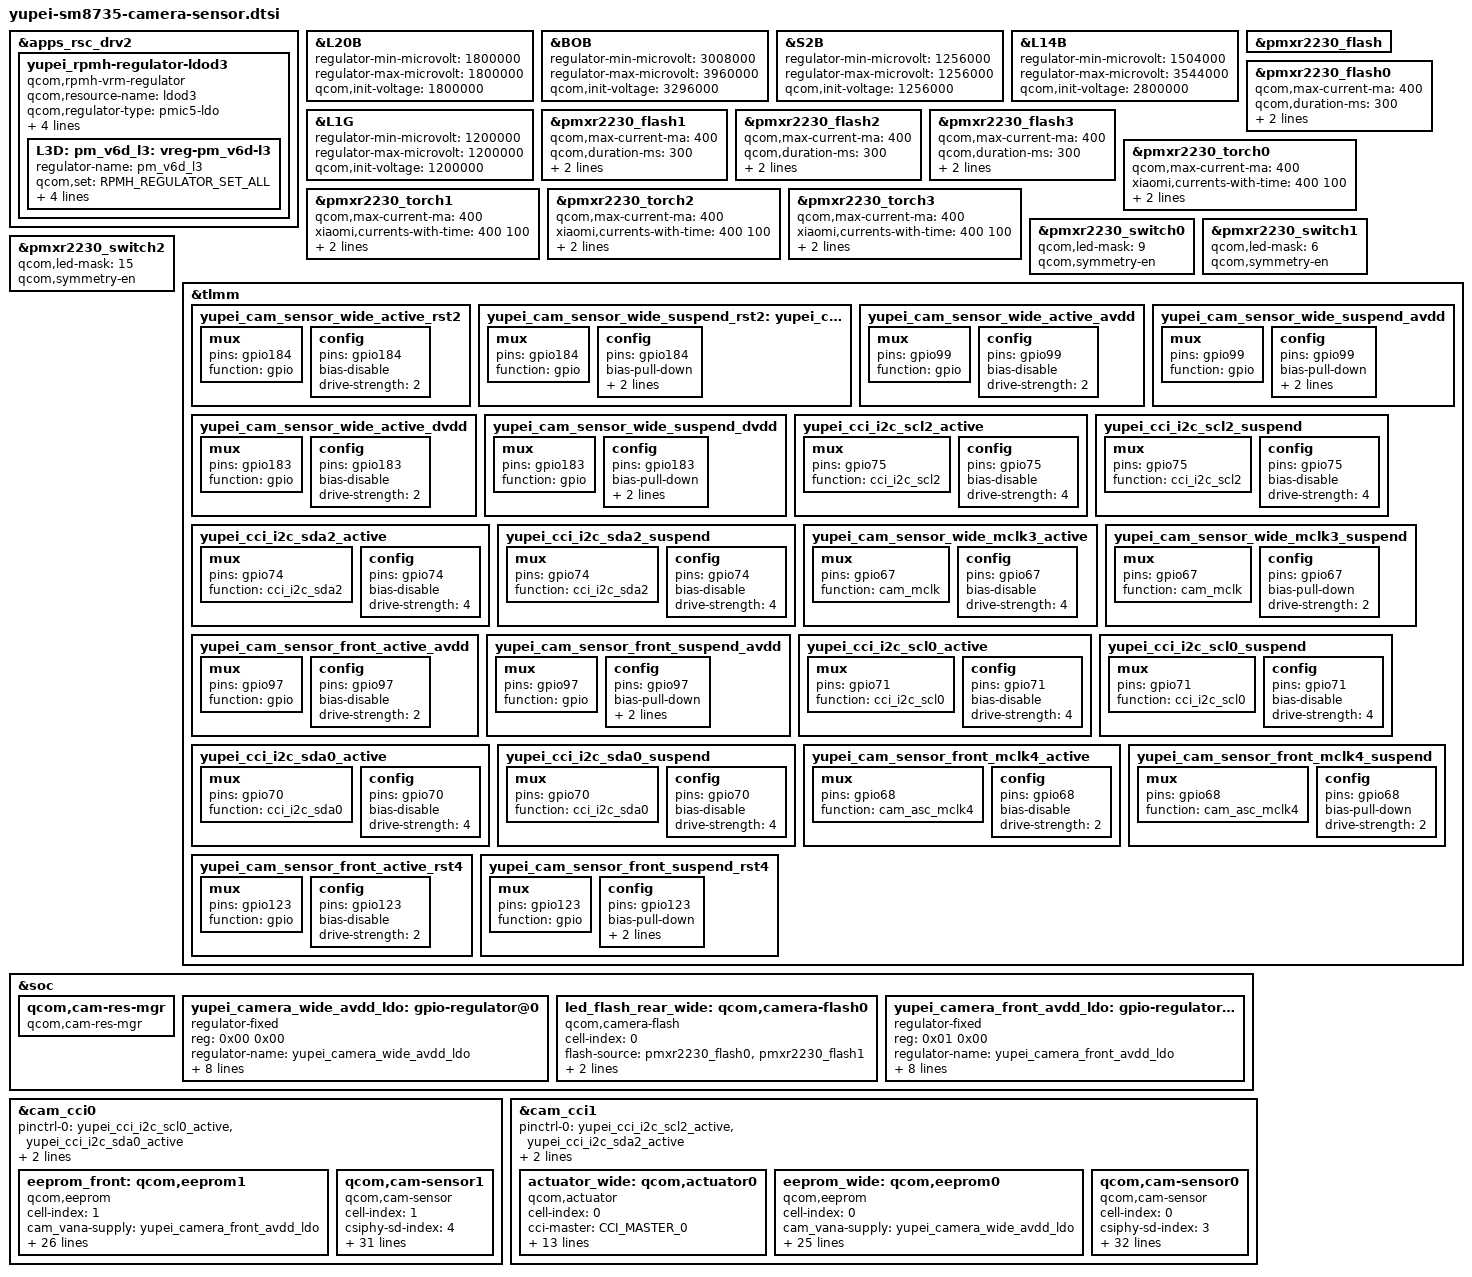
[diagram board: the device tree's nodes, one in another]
#include <dt-bindings/msm-camera.h>

&apps_rsc_drv2 {
	yupei_rpmh-regulator-ldod3 {
		compatible = "qcom,rpmh-vrm-regulator";
		qcom,resource-name = "ldod3";
		qcom,regulator-type = "pmic5-ldo";
		qcom,supported-modes =
			<RPMH_REGULATOR_MODE_LPM
			 RPMH_REGULATOR_MODE_HPM>;
		qcom,mode-threshold-currents = <0 30000>;
		proxy-supply = <&L3D>;

		L3D: pm_v6d_l3: vreg-pm_v6d-l3 {
			regulator-name = "pm_v6d_l3";
			qcom,set = <RPMH_REGULATOR_SET_ALL>;
			regulator-min-microvolt = <1030000>;
			regulator-max-microvolt = <1100000>;
			qcom,init-voltage = <1060000>;
			qcom,init-mode = <RPMH_REGULATOR_MODE_HPM>;
		};
	};
};

&L20B{
	regulator-min-microvolt = <1800000>;
	regulator-max-microvolt = <1800000>;
	qcom,init-voltage = <1800000>;
};

&BOB{
	regulator-min-microvolt = <3008000>;
	regulator-max-microvolt = <3960000>;
	qcom,init-voltage = <3296000>;
};
&S2B{
	regulator-min-microvolt = <1256000>;
	regulator-max-microvolt = <1256000>;
	qcom,init-voltage = <1256000>;
};

&L3D{
	regulator-min-microvolt = <1200000>;
	regulator-max-microvolt = <1200000>;
	qcom,init-voltage = <1200000>;
};

&L14B{
	regulator-min-microvolt = <1504000>;
	regulator-max-microvolt = <3544000>;
	qcom,init-voltage = <2800000>;
	status = "ok";
};

&L1G{
	regulator-min-microvolt = <1200000>;
	regulator-max-microvolt = <1200000>;
	qcom,init-voltage = <1200000>;
};

&pmxr2230_flash {
	status = "ok";
};

&pmxr2230_flash0 {
	qcom,max-current-ma = <400>;
	qcom,duration-ms = <300>;
	xiaomi,max-duration-ms = <300>;
	qcom,ires-ua = <5000>;
};
&pmxr2230_flash1 {
        qcom,max-current-ma = <400>;
        qcom,duration-ms = <300>;
        xiaomi,max-duration-ms = <300>;
        qcom,ires-ua = <5000>;
};
&pmxr2230_flash2 {
        qcom,max-current-ma = <400>;
        qcom,duration-ms = <300>;
        xiaomi,max-duration-ms = <300>;
        qcom,ires-ua = <5000>;
};
&pmxr2230_flash3 {
        qcom,max-current-ma = <400>;
        qcom,duration-ms = <300>;
        xiaomi,max-duration-ms = <300>;
        qcom,ires-ua = <5000>;
};

&pmxr2230_torch0{
	qcom,max-current-ma = <400>;
	xiaomi,currents-with-time = <400 100>;
	xiaomi,time-for-currents = <5000 0xFFFFFFFF>;  /* 0xFFFFFFFF means flash always on*/
	qcom,ires-ua = <5000>;
};
&pmxr2230_torch1{
	qcom,max-current-ma = <400>;
	xiaomi,currents-with-time = <400 100>;
	xiaomi,time-for-currents = <5000 0xFFFFFFFF>;  /* 0xFFFFFFFF means flash always on*/
	qcom,ires-ua = <5000>;
};
&pmxr2230_torch2{
	qcom,max-current-ma = <400>;
	xiaomi,currents-with-time = <400 100>;
	xiaomi,time-for-currents = <5000 0xFFFFFFFF>;  /* 0xFFFFFFFF means flash always on*/
	qcom,ires-ua = <5000>;
};
&pmxr2230_torch3{
        qcom,max-current-ma = <400>;
        xiaomi,currents-with-time = <400 100>;
        xiaomi,time-for-currents = <5000 0xFFFFFFFF>;  /* 0xFFFFFFFF means flash always on*/
        qcom,ires-ua = <5000>;
};

&pmxr2230_switch0 {
	qcom,led-mask = <9>; // Channels 1 & 4
	qcom,symmetry-en;
};
&pmxr2230_switch1 {
	qcom,led-mask = <6>; // Channels 2 & 3
	qcom,symmetry-en;
};
&pmxr2230_switch2 {
	qcom,led-mask = <15>; // Channels All
	qcom,symmetry-en;
};


&tlmm {
		yupei_cam_sensor_wide_active_rst2: yupei_cam_sensor_wide_active_rst2 {
		mux {
			pins = "gpio184";
			function = "gpio";
		};
		config {
			pins = "gpio184";
			bias-disable; /* No PULL */
			drive-strength = <2>; /* 2 MA */
		};
	};
	yupei_cam_sensor_wide_suspend_rst2: yupei_cam_sensor_front_suspend_rst2 {
		mux {
			pins = "gpio184";
			function = "gpio";
		};
		config {
			pins = "gpio184";
			bias-pull-down; /* PULL DOWN */
			drive-strength = <2>; /* 2 MA */
			output-low;
		};
	};

	yupei_cam_sensor_wide_active_avdd: yupei_cam_sensor_wide_active_avdd {
		mux {
			pins = "gpio99";
			function = "gpio";
		};

		config {
			pins = "gpio99";
			bias-disable; /* No PULL */
			drive-strength = <2>; /* 2 MA */
		};
	};

	yupei_cam_sensor_wide_suspend_avdd: yupei_cam_sensor_wide_suspend_avdd {
		mux {
			pins = "gpio99";
			function = "gpio";
		};

		config {
			pins = "gpio99";
			bias-pull-down; /* PULL DOWN */
			drive-strength = <2>; /* 2 MA */
			output-low;
		};
	};


	yupei_cam_sensor_wide_active_dvdd: yupei_cam_sensor_wide_active_dvdd {
		mux {
			pins = "gpio183";
			function = "gpio";
		};

		config {
			pins = "gpio183";
			bias-disable; /* No PULL */
			drive-strength = <2>; /* 2 MA */
		};
	};

	yupei_cam_sensor_wide_suspend_dvdd: yupei_cam_sensor_wide_suspend_dvdd {
		mux {
			pins = "gpio183";
			function = "gpio";
		};

		config {
			pins = "gpio183";
			bias-pull-down; /* PULL DOWN */
			drive-strength = <2>; /* 2 MA */
			output-low;
		};
	};
        
 	yupei_cci_i2c_scl2_active: yupei_cci_i2c_scl2_active {
		mux {
			pins = "gpio75";
			function = "cci_i2c_scl2";
		};
		config {
			pins = "gpio75";
			bias-disable; /* NO PULL */
			drive-strength = <4>; /* 4 MA */
		};
 	};

 	yupei_cci_i2c_scl2_suspend: yupei_cci_i2c_scl2_suspend {
		mux {
			pins = "gpio75";
			function = "cci_i2c_scl2";
		};
		config {
			pins = "gpio75";
			bias-disable; /* NO PULL */
			drive-strength = <4>; /* 4 MA */
		};
 	};     
     
 	yupei_cci_i2c_sda2_active: yupei_cci_i2c_sda2_active {
		mux {
			pins = "gpio74";
			function = "cci_i2c_sda2";
		};
		config {
			pins = "gpio74";
			bias-disable; /* NO PULL */
			drive-strength = <4>; /* 4 MA */
		};
 	};

 	yupei_cci_i2c_sda2_suspend: yupei_cci_i2c_sda2_suspend {
 		mux {
			pins = "gpio74";
			function = "cci_i2c_sda2";
		};
		config {
			pins = "gpio74";
			bias-disable; /* NO PULL */
			drive-strength = <4>; /* 4 MA */
		};
 	};

 	yupei_cam_sensor_wide_mclk3_active: yupei_cam_sensor_wide_mclk3_active {
 		/* MCLK0 */
 		mux {
 			pins = "gpio67";
 			function = "cam_mclk";
 		};

 		config {
 			pins = "gpio67";
 			bias-disable; /* No PULL */
 			drive-strength = <4>; /* 4 MA */
 		};
 	};

 	yupei_cam_sensor_wide_mclk3_suspend: yupei_cam_sensor_wide_mclk3_suspend {
 		/* MCLK0 */
 		mux {
 			pins = "gpio67";
 			function = "cam_mclk";
 		};

 		config {
 			pins = "gpio67";
 			bias-pull-down; /* PULL DOWN */
 			drive-strength = <2>; /* 2 MA */
 		};
 	};

	yupei_cam_sensor_front_active_avdd: yupei_cam_sensor_front_active_avdd {
		mux {
			pins = "gpio97";
			function = "gpio";
		};
		config {
			pins = "gpio97";
			bias-disable; /* No PULL */
			drive-strength = <2>; /* 2 MA */
		};
	};

	yupei_cam_sensor_front_suspend_avdd: yupei_cam_sensor_front_suspend_avdd {
		mux {
			pins = "gpio97";
			function = "gpio";
		};
		config {
			pins = "gpio97";
			bias-pull-down; /* PULL DOWN */
			drive-strength = <2>; /* 2 MA */
			output-low;
		};
	};
        
    yupei_cci_i2c_scl0_active: yupei_cci_i2c_scl0_active {
		mux {
			pins = "gpio71";
			function = "cci_i2c_scl0";
		};

		config {
			pins = "gpio71";
			bias-disable; /* NO PULL */
			drive-strength = <4>; /* 4 MA */
		};
	};

	yupei_cci_i2c_scl0_suspend: yupei_cci_i2c_scl0_suspend {
		mux {
			pins = "gpio71";
			function = "cci_i2c_scl0";
		};
		config {
			pins = "gpio71";
			bias-disable; /* NO PULL */
			drive-strength = <4>; /* 4 MA */
		};
	};

	yupei_cci_i2c_sda0_active: yupei_cci_i2c_sda0_active {
		mux {
			pins = "gpio70";
			function = "cci_i2c_sda0";
		};

		config {
			pins = "gpio70";
			bias-disable; /* NO PULL */
			drive-strength = <4>; /* 4 MA */
		};
	};

	yupei_cci_i2c_sda0_suspend: yupei_cci_i2c_sda0_suspend {
		mux {
			pins = "gpio70";
			function = "cci_i2c_sda0";
		};

		config {
			pins = "gpio70";
			bias-disable; /* NO PULL */
			drive-strength = <4>; /* 4 MA */
		};
	};

	yupei_cam_sensor_front_mclk4_active: yupei_cam_sensor_front_mclk4_active {
		/* MCLK4 */
		mux {
			pins = "gpio68";
			function = "cam_asc_mclk4";
		};
		config {
			pins = "gpio68";
			bias-disable; /* No PULL */
			drive-strength = <2>; /* 2 MA */
		};
	};

	yupei_cam_sensor_front_mclk4_suspend: yupei_cam_sensor_front_mclk4_suspend {
		/* MCLK4 */
		mux {
			pins = "gpio68";
			function = "cam_asc_mclk4";
		};
		config {
			pins = "gpio68";
			bias-pull-down; /* PULL DOWN */
			drive-strength = <2>; /* 2 MA */
		};
	};

	yupei_cam_sensor_front_active_rst4: yupei_cam_sensor_front_active_rst4 {
		mux {
			pins = "gpio123";
			function = "gpio";
		};
		config {
			pins = "gpio123";
			bias-disable; /* No PULL */
			drive-strength = <2>; /* 2 MA */
		};
	};

	yupei_cam_sensor_front_suspend_rst4: yupei_cam_sensor_front_suspend_rst4 {
		mux {
			pins = "gpio123";
			function = "gpio";
		};
		config {
			pins = "gpio123";
			bias-pull-down; /* PULL DOWN */
			drive-strength = <2>; /* 2 MA */
			output-low;
		};
	};

};


&soc {
		qcom,cam-res-mgr {
		compatible = "qcom,cam-res-mgr";
		status = "ok";
	};

	yupei_camera_wide_avdd_ldo: gpio-regulator@0 {
		compatible = "regulator-fixed";
		reg = <0x00 0x00>;
		regulator-name = "yupei_camera_wide_avdd_ldo";
		regulator-min-microvolt = <2800000>;
		regulator-max-microvolt = <2800000>;
		regulator-enable-ramp-delay = <100>;
		enable-active-high;
		gpio = <&tlmm 99 0>;
		pinctrl-names = "yupei_wide_avdd_active", "yupei_wide_avdd_suspend";
		pinctrl-0 = <&yupei_cam_sensor_wide_active_avdd
					 &yupei_cam_sensor_wide_suspend_avdd>;
		vin-supply = <&BOB>;
	};

	/*yupei_camera_wide_dvdd_ldo: gpio-regulator@0 {
		compatible = "regulator-fixed";
		reg = <0x00 0x00>;
		regulator-name = "yupei_camera_wide_dvdd_ldo";
		regulator-min-microvolt = <1200000>;
		regulator-max-microvolt = <1200000>;
		regulator-enable-ramp-delay = <100>;
		enable-active-high;
		gpio = <&tlmm 183 0>;
		pinctrl-names = "yupei_wide_dvdd_active", "yupei_wide_dvdd_suspend";
		pinctrl-0 = <&yupei_cam_sensor_wide_active_dvdd
					 &yupei_cam_sensor_wide_suspend_dvdd>;
		vin-supply = <&BOB &S2B>;

	};*/

	led_flash_rear_wide: qcom,camera-flash0 {
		cell-index = <0>;
		compatible = "qcom,camera-flash";
		flash-source = <&pmxr2230_flash0 &pmxr2230_flash1>;
		torch-source = <&pmxr2230_torch0 &pmxr2230_torch1>;
		switch-source = <&pmxr2230_switch2>;
		status = "ok";
	};

	yupei_camera_front_avdd_ldo: gpio-regulator@1 {
		compatible = "regulator-fixed";
		reg = <0x01 0x00>;
		regulator-name = "yupei_camera_front_avdd_ldo";
		regulator-min-microvolt = <2800000>;
		regulator-max-microvolt = <2800000>;
		regulator-enable-ramp-delay = <100>;
		enable-active-high;
		gpio = <&tlmm 97 0>;
		pinctrl-names = "yupei_front_avdd_active", "yupei_front_avdd_suspend";
		pinctrl-0 = <&yupei_cam_sensor_front_active_avdd
					 &yupei_cam_sensor_front_suspend_avdd>;
		vin-supply = <&BOB>;
	};
};

&cam_cci0 {
	pinctrl-0 = <&yupei_cci_i2c_scl0_active &yupei_cci_i2c_sda0_active>;
	pinctrl-1 = <&yupei_cci_i2c_scl0_suspend &yupei_cci_i2c_sda0_suspend>;

	// front eeprom
	eeprom_front: qcom,eeprom1 {
		cell-index = <1>;
		compatible = "qcom,eeprom";
		cam_vana-supply = <&yupei_camera_front_avdd_ldo>;
		cam_vio-supply = <&L20B>;
		cam_vdig-supply = <&L1G>;
		cam_clk-supply = <&cam_cc_titan_top_gdsc>;
		regulator-names = "cam_vana", "cam_vio", "cam_vdig", "cam_clk";
		rgltr-cntrl-support;
		rgltr-min-voltage = <2800000 1800000 1200000 0>;
		rgltr-max-voltage = <2800000 1800000 1200000 0>;
		rgltr-load-current = <31200 1300 58500 0>;
		gpio-no-mux = <0>;
		pinctrl-names = "cam_default", "cam_suspend";
		pinctrl-0 = <&yupei_cam_sensor_front_mclk4_active
			&yupei_cam_sensor_front_active_rst4>;
		pinctrl-1 = <&yupei_cam_sensor_front_mclk4_suspend
			&yupei_cam_sensor_front_suspend_rst4>;
		gpios = <&tlmm 68 0>, <&tlmm 123 0>;
		gpio-reset = <1>;
		gpio-req-tbl-num = <0 1>;
		gpio-req-tbl-flags = <1 0>;
		gpio-req-tbl-label = "CAMIF_MCLK4", "CAM_RESET4";
		cci-master = <CCI_MASTER_0>;
		clocks = <&cambistmclkcc CAM_BIST_MCLK_CC_MCLK4_CLK>;
		clock-names = "cam_clk";
		clock-cntl-level = "nominal";
		clock-rates = <19200000>;
		status = "ok";
	};

	// front sensor
	qcom,cam-sensor1 {
		cell-index = <1>;
		compatible = "qcom,cam-sensor";
		csiphy-sd-index = <4>;
		eeprom-src = <&eeprom_front>;
		sensor-position-roll = <90>;
		sensor-position-pitch = <0>;
		sensor-position-yaw = <0>;
		cam_vana-supply = <&yupei_camera_front_avdd_ldo>;
		cam_vio-supply = <&L20B>;
		cam_vdig-supply = <&L1G>;
		cam_clk-supply = <&cam_cc_titan_top_gdsc>;
		regulator-names = "cam_vana", "cam_vio", "cam_vdig", "cam_clk";
		rgltr-cntrl-support;
		rgltr-min-voltage = <2800000 1800000 1200000 0>;
		rgltr-max-voltage = <2800000 1800000 1200000 0>;
		rgltr-load-current = <31200 1300 58500 0>;
		gpio-no-mux = <0>;
		pinctrl-names = "cam_default", "cam_suspend";
		pinctrl-0 = <&yupei_cam_sensor_front_mclk4_active
			&yupei_cam_sensor_front_active_rst4>;
		pinctrl-1 = <&yupei_cam_sensor_front_mclk4_suspend
			&yupei_cam_sensor_front_suspend_rst4>;
		gpios = <&tlmm 68 0>, <&tlmm 123 0>;
		gpio-reset = <1>;
		gpio-req-tbl-num = <0 1>;
		gpio-req-tbl-flags = <1 0>;
		gpio-req-tbl-label = "CAMIF_MCLK4", "CAM_RESET4";
		cci-master = <CCI_MASTER_0>;
		clocks = <&cambistmclkcc CAM_BIST_MCLK_CC_MCLK4_CLK>;
		clock-names = "cam_clk";
		clock-cntl-level = "nominal";
		clock-rates = <19200000>;
		status = "ok";
	};
};

&cam_cci1 {
	pinctrl-0 = <&yupei_cci_i2c_scl2_active &yupei_cci_i2c_sda2_active>;
	pinctrl-1 = <&yupei_cci_i2c_scl2_suspend &yupei_cci_i2c_sda2_suspend>;

	// wide actuator
	actuator_wide: qcom,actuator0 {
		cell-index = <0>;
		compatible = "qcom,actuator";
		cci-master = <CCI_MASTER_0>;
  		cam_vana-supply = <&yupei_camera_wide_avdd_ldo>;
  		cam_vio-supply = <&L20B>;
  		cam_vdig-supply = <&L3D>;
		cam_clk-supply = <&cam_cc_titan_top_gdsc>;
		cam_vaf-supply = <&L14B>;
		regulator-names = "cam_vana", "cam_vio",
			"cam_vdig", "cam_clk", "cam_vaf";
		rgltr-cntrl-support;
		rgltr-min-voltage = <2800000 1800000 1200000 0 2800000>;
		rgltr-max-voltage = <2800000 1800000 1200000 0 2800000>;
		rgltr-load-current = <45000 3000 130000 0 120000>;
	};

	eeprom_wide: qcom,eeprom0 {
		cell-index = <0>;
		compatible = "qcom,eeprom";
  		cam_vana-supply = <&yupei_camera_wide_avdd_ldo>;
  		cam_vio-supply = <&L20B>;
  		cam_vdig-supply = <&L3D>;
		cam_clk-supply = <&cam_cc_titan_top_gdsc>;
		regulator-names = "cam_vana", "cam_vio", "cam_vdig", "cam_clk";
		rgltr-cntrl-support;
		rgltr-min-voltage = <2800000  1800000 1200000  0 >;
		rgltr-max-voltage = <2800000  1800000 1200000 0 >;
		rgltr-load-current = <45000   3000  130000  0 >;
		//use-shared-clk;
  		gpio-no-mux = <0>;
  		pinctrl-names = "cam_default", "cam_suspend";
  		pinctrl-0 = <&yupei_cam_sensor_wide_mclk3_active
			&yupei_cam_sensor_wide_active_rst2>;
		pinctrl-1 = <&yupei_cam_sensor_wide_mclk3_suspend
			&yupei_cam_sensor_wide_suspend_rst2>;
  		gpios = <&tlmm 67 0>, <&tlmm 184 0>;
		gpio-reset = <1>;
		gpio-req-tbl-num = <0 1>;
		gpio-req-tbl-flags = <1 0>;
		gpio-req-tbl-label = "CAMIF_MCLK3", "CAM_RESET2";
		cci-master = <CCI_MASTER_0>;
  		clocks = <&cambistmclkcc CAM_BIST_MCLK_CC_MCLK3_CLK>;
		clock-names = "cam_clk";
		clock-cntl-level = "nominal";
		clock-rates = <19200000>;
		status = "ok";
	};

 	// wide sensor
  	qcom,cam-sensor0 {
  		cell-index = <0>;
  		compatible = "qcom,cam-sensor";
  		csiphy-sd-index = <3>;
  		actuator-src = <&actuator_wide>;
  		eeprom-src = <&eeprom_wide>;
  		led-flash-src = <&led_flash_rear_wide>;
  		//ois-src = <&ois_wide>;
  		sensor-position-roll = <90>;
  		sensor-position-pitch = <0>;
  		sensor-position-yaw = <180>;
  		cam_vana-supply = <&yupei_camera_wide_avdd_ldo>;
  		cam_vio-supply = <&L20B>;
  		cam_vdig-supply = <&L3D>;
		//cam_v_custom1-supply = <&yupei_camera_wide_dvdd_ldo>;
  		//cam_vaf-supply = <&L14B>;
  		cam_clk-supply = <&cam_cc_titan_top_gdsc>;
  		regulator-names = "cam_vana", "cam_vio", "cam_vdig", /*"cam_v_custom1", "cam_vaf",*/ "cam_clk";
  		rgltr-cntrl-support;
  		rgltr-min-voltage = <2800000  1800000 1200000 0>;
  		rgltr-max-voltage = <2800000  1800000 1200000 0>;
  		rgltr-load-current = <45000   3000  130000 0>;
  		//use-shared-clk;
  		gpio-no-mux = <0>;
  		pinctrl-names = "cam_default", "cam_suspend";
  		pinctrl-0 = <&yupei_cam_sensor_wide_mclk3_active
			&yupei_cam_sensor_wide_active_rst2>;
		pinctrl-1 = <&yupei_cam_sensor_wide_mclk3_suspend
			&yupei_cam_sensor_wide_suspend_rst2>;
  		gpios = <&tlmm 67 0>, <&tlmm 184 0>;
  		gpio-reset = <1>;
  		gpio-req-tbl-num = <0 1>;
  		gpio-req-tbl-flags = <1 0>;
  		gpio-req-tbl-label = "CAMIF_MCLK3", "CAM_RESET2";
  		cci-master = <CCI_MASTER_0>;
  		clocks = <&cambistmclkcc CAM_BIST_MCLK_CC_MCLK3_CLK>;
  		clock-names = "cam_clk";
  		clock-cntl-level = "nominal";
  		clock-rates = <19200000>;
  		status = "ok";
  	};

};
